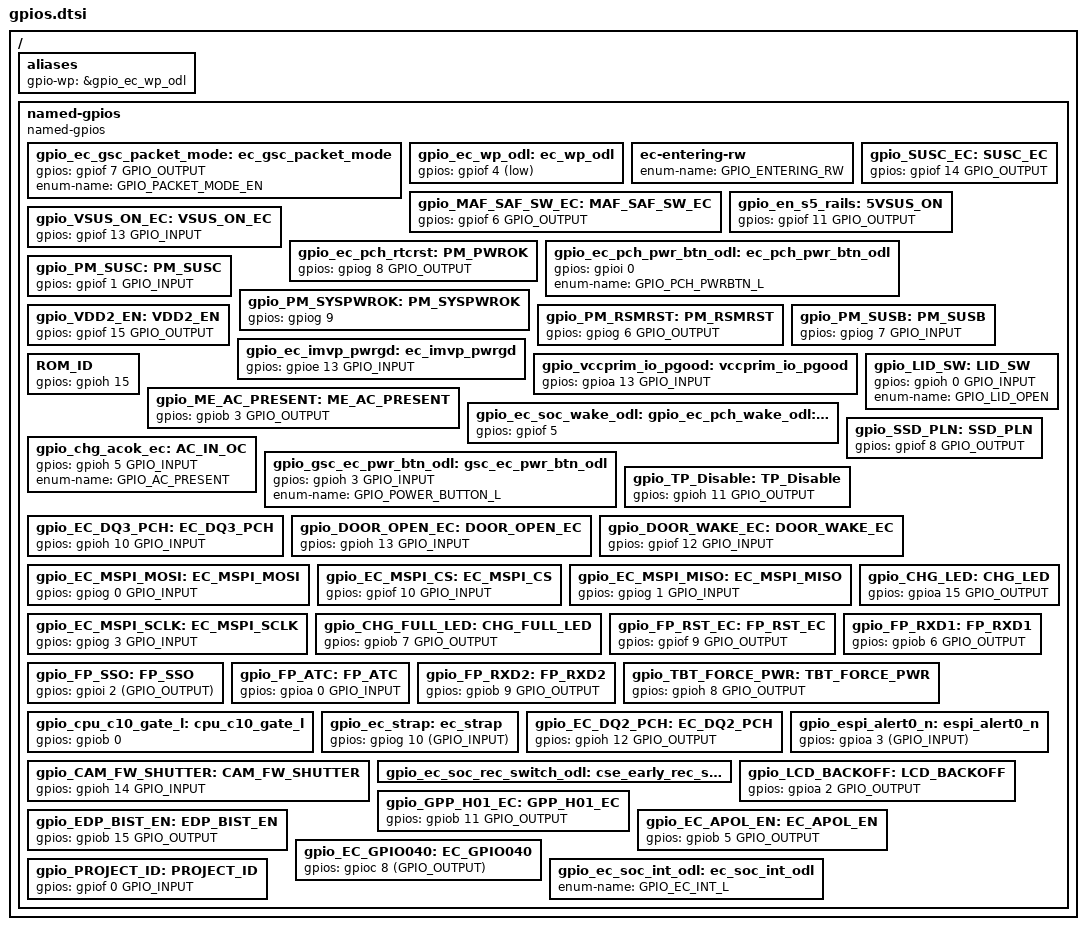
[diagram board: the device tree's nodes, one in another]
/* Copyright 2025 The ChromiumOS Authors
 * Use of this source code is governed by a BSD-style license that can be
 * found in the LICENSE file.
 */

/ {
	aliases {
		gpio-wp = &gpio_ec_wp_odl;
	};

	named-gpios {
		compatible = "named-gpios";

		gpio_ec_gsc_packet_mode: ec_gsc_packet_mode {
			gpios = <&gpiof 7 GPIO_OUTPUT>;
			enum-name = "GPIO_PACKET_MODE_EN";
		};
		gpio_ec_wp_odl: ec_wp_odl {
			gpios = <&gpiof 4 (GPIO_INPUT | GPIO_ACTIVE_LOW)>;
		};
		/* The legacy system code requires GPIO_ENTERING_RW symbol */
		ec-entering-rw {
			enum-name = "GPIO_ENTERING_RW";
		};
		
		gpio_MAF_SAF_SW_EC: MAF_SAF_SW_EC {
			gpios = <&gpiof 6 GPIO_OUTPUT>;
		};

		// A13
		gpio_SUSC_EC: SUSC_EC {
			gpios = <&gpiof 14 GPIO_OUTPUT>;
		};
		gpio_en_s5_rails: 5VSUS_ON {
			gpios = <&gpiof 11 GPIO_OUTPUT>;
		};
		// A5
		gpio_VSUS_ON_EC: VSUS_ON_EC {
			gpios = <&gpiof 13 GPIO_INPUT>;
		};
		// PTL_PWROK
		gpio_ec_pch_rtcrst: PM_PWROK {
			gpios = <&gpiog 8 GPIO_OUTPUT>;
		};
		gpio_ec_pch_pwr_btn_odl: ec_pch_pwr_btn_odl {
			gpios = <&gpioi 0 (GPIO_OUTPUT | GPIO_OPEN_DRAIN | GPIO_ACTIVE_HIGH | GPIO_OUTPUT_INIT_HIGH)>;
			enum-name = "GPIO_PCH_PWRBTN_L";
		};
		// slp_s4
		gpio_PM_SUSC: PM_SUSC {
			gpios = <&gpiof 1 GPIO_INPUT>;
		};
		// SYS_PWROK
		gpio_PM_SYSPWROK: PM_SYSPWROK {
			gpios = <&gpiog 9 (GPIO_OUTPUT | GPIO_OPEN_DRAIN | GPIO_ACTIVE_HIGH | GPIO_OUTPUT_INIT_HIGH)>;
		};
		// A12
		gpio_VDD2_EN: VDD2_EN {
			gpios = <&gpiof 15 GPIO_OUTPUT>;
		};
		gpio_PM_RSMRST: PM_RSMRST {
			gpios = <&gpiog 6 GPIO_OUTPUT>;
		};
		gpio_ec_imvp_pwrgd: ec_imvp_pwrgd {
			gpios = <&gpioe 13 GPIO_INPUT>;
		};
		// slp_s3
		gpio_PM_SUSB: PM_SUSB {
			gpios = <&gpiog 7 GPIO_INPUT>;
		};
		// sys_rst_odl
		ROM_ID: ROM_ID {
			gpios = <&gpioh 15 (GPIO_OUTPUT | GPIO_OPEN_DRAIN | GPIO_ACTIVE_HIGH | GPIO_OUTPUT_INIT_HIGH)>;
		};
		gpio_vccprim_io_pgood: vccprim_io_pgood {
			gpios = <&gpioa 13 GPIO_INPUT>;
		};
		gpio_ME_AC_PRESENT: ME_AC_PRESENT {
			gpios = <&gpiob 3 GPIO_OUTPUT>;
		};
		/* Not to be marked as active low, the lpc_update_wake() already has the logic to invert the value. */
		gpio_ec_soc_wake_odl: ec_soc_wake_odl {
			gpios = <&gpiof 5 (GPIO_OUTPUT | GPIO_OPEN_DRAIN | GPIO_OUTPUT_INIT_LOW)>;
		};

		// A3
		gpio_LID_SW: LID_SW {
			gpios = <&gpioh 0 GPIO_INPUT>;
			enum-name = "GPIO_LID_OPEN";
		};
		// A4
		gpio_chg_acok_ec: AC_IN_OC {
			gpios = <&gpioh 5 GPIO_INPUT>;
			enum-name = "GPIO_AC_PRESENT";
		};
		gpio_gsc_ec_pwr_btn_odl: gsc_ec_pwr_btn_odl {
			gpios = <&gpioh 3 GPIO_INPUT>;
			enum-name = "GPIO_POWER_BUTTON_L";
		};
		gpio_SSD_PLN: SSD_PLN {
			gpios = <&gpiof 8 GPIO_OUTPUT>;
		};
		gpio_TP_Disable: TP_Disable {
			gpios = <&gpioh 11 GPIO_OUTPUT>;
		};
		gpio_EC_DQ3_PCH: EC_DQ3_PCH {
			gpios = <&gpioh 10 GPIO_INPUT>;
		};

		gpio_DOOR_OPEN_EC: DOOR_OPEN_EC {
			gpios = <&gpioh 13 GPIO_INPUT>;
		};
		gpio_DOOR_WAKE_EC: DOOR_WAKE_EC {
			gpios = <&gpiof 12 GPIO_INPUT>;
		};		

		// D9
		gpio_EC_MSPI_MOSI: EC_MSPI_MOSI {
			gpios = <&gpiog 0 GPIO_INPUT>;
		};
		gpio_EC_MSPI_CS: EC_MSPI_CS {
			gpios = <&gpiof 10 GPIO_INPUT>;
		};
		gpio_EC_MSPI_MISO: EC_MSPI_MISO {
			gpios = <&gpiog 1 GPIO_INPUT>;
		};
		gpio_EC_MSPI_SCLK: EC_MSPI_SCLK {
			gpios = <&gpiog 3 GPIO_INPUT>;
		};

		gpio_CHG_LED: CHG_LED {
			gpios = <&gpioa 15 GPIO_OUTPUT>;
		};
		gpio_CHG_FULL_LED: CHG_FULL_LED {
			gpios = <&gpiob 7 GPIO_OUTPUT>;
		};

		// A10
		gpio_FP_RST_EC: FP_RST_EC {
			gpios = <&gpiof 9 GPIO_OUTPUT>;
		};
		gpio_FP_RXD1: FP_RXD1 {
			gpios = <&gpiob 6 GPIO_OUTPUT>;
		};
		gpio_FP_SSO: FP_SSO {
			gpios = <&gpioi 2 (GPIO_OUTPUT)>;
		};
		gpio_FP_ATC: FP_ATC {
			gpios = <&gpioa 0 GPIO_INPUT>;
		};
		gpio_FP_RXD2: FP_RXD2 {
			gpios = <&gpiob 9 GPIO_OUTPUT>;
		};

		gpio_TBT_FORCE_PWR: TBT_FORCE_PWR {
			gpios = <&gpioh 8 GPIO_OUTPUT>;
		};
		// gpio_edp_bklt_en: edp_bklt_en {
		// 	gpios = <&gpioh 9 (GPIO_INPUT | GPIO_VOLTAGE_1P8)>;
		// };		
		gpio_cpu_c10_gate_l: cpu_c10_gate_l {
			gpios = <&gpiob 0 (GPIO_INPUT | GPIO_VOLTAGE_1P8)>;
		};
		gpio_ec_strap: ec_strap {
			gpios = <&gpiog 10 (GPIO_INPUT)>;
		};
		gpio_EC_DQ2_PCH: EC_DQ2_PCH {
			gpios = <&gpioh 12 GPIO_OUTPUT>;
		};
		gpio_CAM_FW_SHUTTER: CAM_FW_SHUTTER {
			gpios = <&gpioh 14 GPIO_INPUT>;
		};
		gpio_ec_soc_rec_switch_odl: ec_soc_rec_switch_odl {
			// gpios = <&gpioi 2 (GPIO_INPUT)>;
		};
		gpio_espi_alert0_n: espi_alert0_n {
			gpios = <&gpioa 3 (GPIO_INPUT)>;
		};
		gpio_LCD_BACKOFF: LCD_BACKOFF {
			gpios = <&gpioa 2 GPIO_OUTPUT>;
		};
		// gpio_FAN1_PWM: FAN1_PWM {
		// 	gpios = <&gpiob 12 GPIO_OUTPUT>;
		// };
		gpio_GPP_H01_EC: GPP_H01_EC {
			gpios = <&gpiob 11 GPIO_OUTPUT>;
		};
		gpio_EDP_BIST_EN: EDP_BIST_EN {
			gpios = <&gpiob 15 GPIO_OUTPUT>;
		};
		gpio_EC_APOL_EN: EC_APOL_EN {
			gpios = <&gpiob 5 GPIO_OUTPUT>;
		};
		gpio_EC_GPIO040: EC_GPIO040 {
			gpios = <&gpioc 8 (GPIO_OUTPUT)>;
		};
		gpio_PROJECT_ID: PROJECT_ID {
			gpios = <&gpiof 0 GPIO_INPUT>;
		};
		gpio_ec_soc_int_odl: ec_soc_int_odl {
			// gpios = <&gpioa 13 (GPIO_OUTPUT | GPIO_OPEN_DRAIN | GPIO_ACTIVE_HIGH | GPIO_OUTPUT_INIT_HIGH)>;
			enum-name = "GPIO_EC_INT_L";
		};
	};
};

/*
 * Aliases to common names
 */
gpio_ec_pch_wake_odl: &gpio_ec_soc_wake_odl {};
cse_early_rec_sw: &gpio_ec_soc_rec_switch_odl {};
